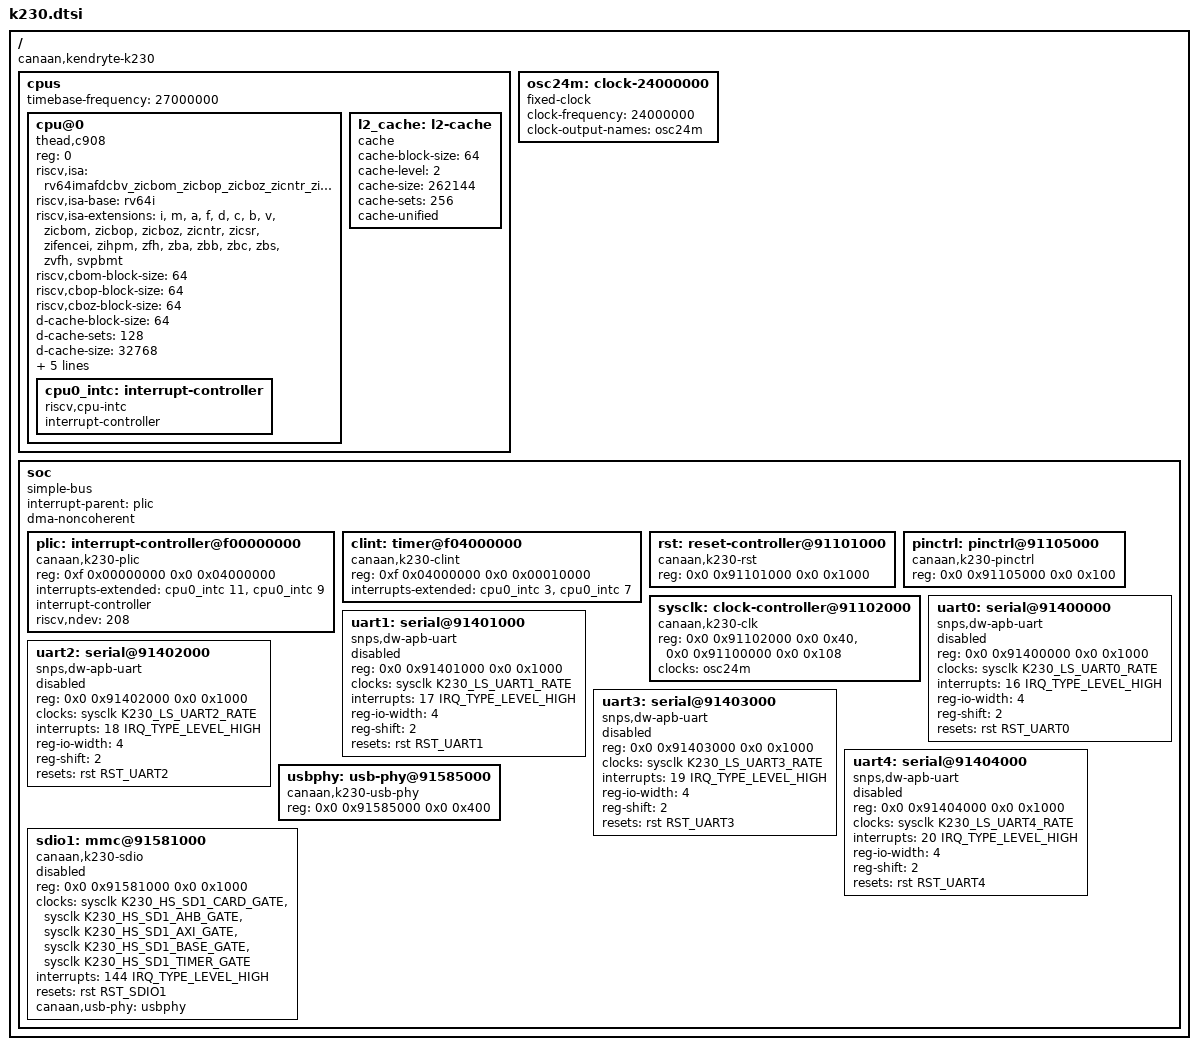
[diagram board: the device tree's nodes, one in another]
// SPDX-License-Identifier: GPL-2.0 OR MIT
/*
 * Copyright (C) 2024 Yangyu Chen <cyy@cyyself.name>
 *
 * Elixos copy (ADR-101): arch/riscv/boot/dts/canaan/k230.dtsi from Linux
 * v7.3 (sha256 65b9156e2df52d0f6f96dde648fcb560342afcc5148faf5a2b9576d0cbe4a7ca),
 * unchanged above the "Elixos additions" marker. Our pinned kernel (7.2.9)
 * ships the drivers and dt-bindings headers this file needs but not the file.
 * Below the marker: the nodes mainline has not merged yet, written against
 * the 7.2.9 bindings (canaan,k230-usb-phy.yaml, snps,dwcmshc-sdhci.yaml).
 */

#include <dt-bindings/clock/canaan,k230-clk.h>
#include <dt-bindings/interrupt-controller/irq.h>
#include <dt-bindings/reset/canaan,k230-rst.h>
#include "k230-pinctrl.h"

/dts-v1/;
/ {
	#address-cells = <2>;
	#size-cells = <2>;
	compatible = "canaan,kendryte-k230";

	cpus {
		#address-cells = <1>;
		#size-cells = <0>;
		timebase-frequency = <27000000>;

		cpu@0 {
			compatible = "thead,c908", "riscv";
			device_type = "cpu";
			reg = <0>;
			riscv,isa = "rv64imafdcbv_zicbom_zicbop_zicboz_zicntr_zicsr_zifencei_zihpm_zfh_zba_zbb_zbc_zbs_zvfh_svpbmt";
			riscv,isa-base = "rv64i";
			riscv,isa-extensions = "i", "m", "a", "f", "d", "c", "b", "v", "zicbom",
					       "zicbop", "zicboz", "zicntr", "zicsr", "zifencei",
					       "zihpm", "zfh", "zba", "zbb", "zbc", "zbs", "zvfh",
					       "svpbmt";
			riscv,cbom-block-size = <64>;
			riscv,cbop-block-size = <64>;
			riscv,cboz-block-size = <64>;
			d-cache-block-size = <64>;
			d-cache-sets = <128>;
			d-cache-size = <32768>;
			i-cache-block-size = <64>;
			i-cache-sets = <128>;
			i-cache-size = <32768>;
			next-level-cache = <&l2_cache>;
			mmu-type = "riscv,sv39";

			cpu0_intc: interrupt-controller {
				compatible = "riscv,cpu-intc";
				interrupt-controller;
				#interrupt-cells = <1>;
			};
		};

		l2_cache: l2-cache {
			compatible = "cache";
			cache-block-size = <64>;
			cache-level = <2>;
			cache-size = <262144>;
			cache-sets = <256>;
			cache-unified;
		};
	};

	osc24m: clock-24000000 {
		compatible = "fixed-clock";
		#clock-cells = <0>;
		clock-frequency = <24000000>;
		clock-output-names = "osc24m";
	};

	soc {
		compatible = "simple-bus";
		interrupt-parent = <&plic>;
		#address-cells = <2>;
		#size-cells = <2>;
		dma-noncoherent;
		ranges;

		plic: interrupt-controller@f00000000 {
			compatible = "canaan,k230-plic", "thead,c900-plic";
			reg = <0xf 0x00000000 0x0 0x04000000>;
			interrupts-extended = <&cpu0_intc 11>, <&cpu0_intc 9>;
			interrupt-controller;
			#address-cells = <0>;
			#interrupt-cells = <2>;
			riscv,ndev = <208>;
		};

		clint: timer@f04000000 {
			compatible = "canaan,k230-clint", "thead,c900-clint";
			reg = <0xf 0x04000000 0x0 0x00010000>;
			interrupts-extended = <&cpu0_intc 3>, <&cpu0_intc 7>;
		};

		rst: reset-controller@91101000 {
			compatible = "canaan,k230-rst";
			reg = <0x0 0x91101000 0x0 0x1000>;
			#reset-cells = <1>;
		};

		pinctrl: pinctrl@91105000 {
			compatible = "canaan,k230-pinctrl";
			reg = <0x0 0x91105000 0x0 0x100>;
		};

		sysclk: clock-controller@91102000 {
			compatible = "canaan,k230-clk";
			reg = <0x0 0x91102000 0x0 0x40>,
			      <0x0 0x91100000 0x0 0x108>;
			clocks = <&osc24m>;
			clock-names = "osc24m";
			#clock-cells = <1>;
		};

		uart0: serial@91400000 {
			compatible = "snps,dw-apb-uart";
			reg = <0x0 0x91400000 0x0 0x1000>;
			clocks = <&sysclk K230_LS_UART0_RATE>;
			interrupts = <16 IRQ_TYPE_LEVEL_HIGH>;
			reg-io-width = <4>;
			reg-shift = <2>;
			resets = <&rst RST_UART0>;
			status = "disabled";
		};

		uart1: serial@91401000 {
			compatible = "snps,dw-apb-uart";
			reg = <0x0 0x91401000 0x0 0x1000>;
			clocks = <&sysclk K230_LS_UART1_RATE>;
			interrupts = <17 IRQ_TYPE_LEVEL_HIGH>;
			reg-io-width = <4>;
			reg-shift = <2>;
			resets = <&rst RST_UART1>;
			status = "disabled";
		};

		uart2: serial@91402000 {
			compatible = "snps,dw-apb-uart";
			reg = <0x0 0x91402000 0x0 0x1000>;
			clocks = <&sysclk K230_LS_UART2_RATE>;
			interrupts = <18 IRQ_TYPE_LEVEL_HIGH>;
			reg-io-width = <4>;
			reg-shift = <2>;
			resets = <&rst RST_UART2>;
			status = "disabled";
		};

		uart3: serial@91403000 {
			compatible = "snps,dw-apb-uart";
			reg = <0x0 0x91403000 0x0 0x1000>;
			clocks = <&sysclk K230_LS_UART3_RATE>;
			interrupts = <19 IRQ_TYPE_LEVEL_HIGH>;
			reg-io-width = <4>;
			reg-shift = <2>;
			resets = <&rst RST_UART3>;
			status = "disabled";
		};

		uart4: serial@91404000 {
			compatible = "snps,dw-apb-uart";
			reg = <0x0 0x91404000 0x0 0x1000>;
			clocks = <&sysclk K230_LS_UART4_RATE>;
			interrupts = <20 IRQ_TYPE_LEVEL_HIGH>;
			reg-io-width = <4>;
			reg-shift = <2>;
			resets = <&rst RST_UART4>;
			status = "disabled";
		};

		/* Elixos additions (ADR-101). */

		/*
		 * The HSI system-config block. The USB PHY driver owns its USB
		 * half; the SDHCI driver maps the whole node as a regmap for the
		 * SD0/SD1 control registers (sdhci-of-dwcmshc.c, canaan,usb-phy).
		 */
		usbphy: usb-phy@91585000 {
			compatible = "canaan,k230-usb-phy";
			reg = <0x0 0x91585000 0x0 0x400>;
			#phy-cells = <1>;
		};

		/*
		 * SDIO1. The driver takes "core" and "bus" by name and "axi",
		 * "block", "timer" as optional clocks (7.2.9,
		 * sdhci-of-dwcmshc.c:1951, 2426, 2435). Interrupt 144 is the
		 * number used by the posted mainline mmc-node patch (linux-riscv,
		 * 2026-02-04) and by Canaan's SDK device tree.
		 */
		sdio1: mmc@91581000 {
			compatible = "canaan,k230-sdio";
			reg = <0x0 0x91581000 0x0 0x1000>;
			clocks = <&sysclk K230_HS_SD1_CARD_GATE>,
				 <&sysclk K230_HS_SD1_AHB_GATE>,
				 <&sysclk K230_HS_SD1_AXI_GATE>,
				 <&sysclk K230_HS_SD1_BASE_GATE>,
				 <&sysclk K230_HS_SD1_TIMER_GATE>;
			clock-names = "core", "bus", "axi", "block", "timer";
			interrupts = <144 IRQ_TYPE_LEVEL_HIGH>;
			resets = <&rst RST_SDIO1>;
			canaan,usb-phy = <&usbphy>;
			status = "disabled";
		};
	};
};
